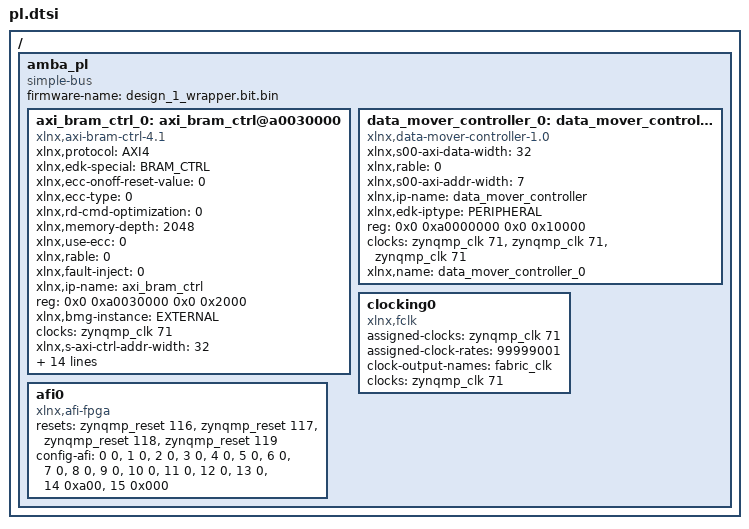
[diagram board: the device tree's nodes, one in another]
/ {
	amba_pl: amba_pl {
		ranges;
		compatible = "simple-bus";
		#address-cells = <2>;
		#size-cells = <2>;
		firmware-name = "design_1_wrapper.bit.bin";
		axi_bram_ctrl_0: axi_bram_ctrl@a0030000 {
			xlnx,protocol = "AXI4";
			xlnx,edk-special = "BRAM_CTRL";
			compatible = "xlnx,axi-bram-ctrl-4.1";
			xlnx,ecc-onoff-reset-value = <0>;
			xlnx,ecc-type = <0>;
			xlnx,rd-cmd-optimization = <0>;
			xlnx,memory-depth = <2048>;
			xlnx,use-ecc = <0>;
			xlnx,rable = <0>;
			xlnx,fault-inject = <0>;
			xlnx,ip-name = "axi_bram_ctrl";
			reg = <0x0 0xa0030000 0x0 0x2000>;
			xlnx,bmg-instance = "EXTERNAL";
			clocks = <&zynqmp_clk 71>;
			xlnx,s-axi-ctrl-addr-width = <32>;
			xlnx,read-latency = <1>;
			xlnx,s-axi-supports-narrow-burst = <0>;
			xlnx,id-width = <0>;
			xlnx,supports-narrow-burst = <0>;
			xlnx,single-port-bram = <0>;
			xlnx,ecc = <0>;
			xlnx,edk-iptype = "PERIPHERAL";
			status = "okay";
			clock-names = "s_axi_aclk";
			xlnx,bram-addr-width = <11>;
			xlnx,bram-inst-mode = "EXTERNAL";
			xlnx,data-width = <32>;
			xlnx,s-axi-ctrl-data-width = <32>;
			xlnx,s-axi-id-width = <1>;
			xlnx,mem-depth = <2048>;
			xlnx,name = "axi_bram_ctrl_0";
		};
		data_mover_controller_0: data_mover_controller@a0000000 {
			xlnx,s00-axi-data-width = <32>;
			xlnx,rable = <0>;
			compatible = "xlnx,data-mover-controller-1.0";
			status = "okay";
			clock-names = "m00_axis_aclk" , "s00_axi_aclk" , "s00_axis_aclk";
			xlnx,s00-axi-addr-width = <7>;
			xlnx,ip-name = "data_mover_controller";
			xlnx,edk-iptype = "PERIPHERAL";
			reg = <0x0 0xa0000000 0x0 0x10000>;
			clocks = <&zynqmp_clk 71>, <&zynqmp_clk 71>, <&zynqmp_clk 71>;
			xlnx,name = "data_mover_controller_0";
		};
		clocking0: clocking0 {
			compatible = "xlnx,fclk";
			assigned-clocks = <&zynqmp_clk 71>;
			assigned-clock-rates = <99999001>;
			#clock-cells = <0>;
			clock-output-names = "fabric_clk";
			clocks = <&zynqmp_clk 71>;
		};
		afi0: afi0 {
			status = "okay";
			compatible = "xlnx,afi-fpga";
			resets = <&zynqmp_reset 116>, <&zynqmp_reset 117>, <&zynqmp_reset 118>, <&zynqmp_reset 119>;
			config-afi = < 0 0>, <1 0>, <2 0>, <3 0>, <4 0>, <5 0>, <6 0>, <7 0>, <8 0>, <9 0>, <10 0>, <11 0>, <12 0>, <13 0>, <14 0xa00>, <15 0x000>;
		};
	};
};
